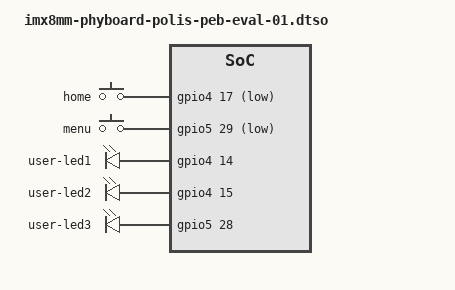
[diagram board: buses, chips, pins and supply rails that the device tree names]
// SPDX-License-Identifier: GPL-2.0
/*
 * Copyright (C) 2025 PHYTEC Messtechnik GmbH
 * Author: Janine Hagemann <j.hagemann@phytec.de>
 */

/dts-v1/;
/plugin/;

#include <dt-bindings/gpio/gpio.h>
#include <dt-bindings/input/linux-event-codes.h>
#include "imx8mm-pinfunc.h"

&{/} {
	gpio-keys {
		compatible = "gpio-keys";
		pinctrl-names = "default";
		pinctrl-0 = <&pinctrl_gpio_keys>;

		button-0 {
			label = "home";
			linux,code = <KEY_HOME>;
			gpios = <&gpio4 17 GPIO_ACTIVE_LOW>;
			wakeup-source;
		};

		button-1 {
			label = "menu";
			linux,code = <KEY_MENU>;
			gpios = <&gpio5 29 GPIO_ACTIVE_LOW>;
			wakeup-source;
		};
	};

	user-leds {
		compatible = "gpio-leds";
		pinctrl-names = "default";
		pinctrl-0 = <&pinctrl_user_leds>;

		user-led1 {
			gpios = <&gpio4 14 GPIO_ACTIVE_HIGH>;
			default-state = "on";
		};

		user-led2 {
			gpios = <&gpio4 15 GPIO_ACTIVE_HIGH>;
			default-state = "on";
		};

		user-led3 {
			gpios = <&gpio5 28 GPIO_ACTIVE_HIGH>;
			default-state = "on";
		};
	};
};

&iomuxc {
	pinctrl_gpio_keys: gpio_keysgrp {
		fsl,pins = <
			MX8MM_IOMUXC_SAI1_TXD5_GPIO4_IO17	0x16
			MX8MM_IOMUXC_UART4_TXD_GPIO5_IO29	0x16
		>;
	};

	pinctrl_user_leds: user_ledsgrp {
		fsl,pins = <
			MX8MM_IOMUXC_SAI1_TXD3_GPIO4_IO15	0x16
			MX8MM_IOMUXC_UART4_RXD_GPIO5_IO28	0x16
			MX8MM_IOMUXC_SAI1_TXD2_GPIO4_IO14	0x16
		>;
	};
};
